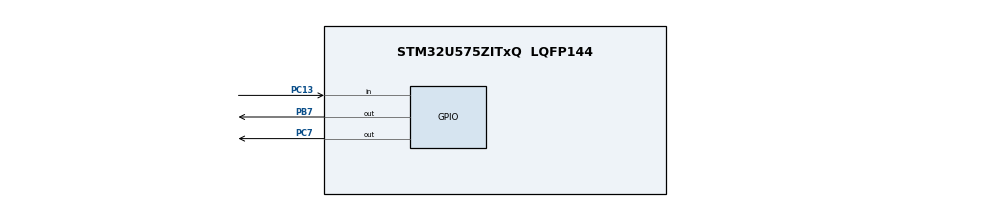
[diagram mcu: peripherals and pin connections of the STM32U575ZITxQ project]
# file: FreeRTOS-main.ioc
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CORTEX_M33_NS.userName=CORTEX_M33
Mcu.Family=STM32U5
Mcu.Name=STM32U575ZITxQ
Mcu.Package=LQFP144
NVIC.PriorityGroup=NVIC_PRIORITYGROUP_4
NVIC.TIM6_IRQn=true\:15\:0\:false\:false\:true\:false\:true\:true
NVIC.TimeBase=TIM6_IRQn
NVIC.TimeBaseIP=TIM6
PB7.Signal=GPIO_Output
PC13.Signal=GPIO_Input
PC7.Signal=GPIO_Output
ProjectManager.HeapSize=0x200
ProjectManager.StackSize=0x400
ProjectManager.TargetToolchain=STM32CubeIDE
RCC.ADCFreq_Value=16000000
RCC.EPOD_VALUE=4000000
RCC.HSE_VALUE=16000000
RCC.HSI48_VALUE=48000000
RCC.HSI_VALUE=16000000
RCC.LSE_VALUE=32768
RCC.LSIDIV_VALUE=32000
RCC.MSI_VALUE=4000000
RCC.USBFreq_Value=48000000
RCC.VCOOutputFreq_Value=516000000
VP_LPBAMQUEUE_VS_QUEUE.Mode=QUEUEMODE
VP_LPBAM_VS_SIG1.Mode=SmartRun
VP_LPBAM_VS_SIG4.Mode=LPDMA1
VP_MEMORYMAP_VS_MEMORYMAP.Mode=CurAppReg
VP_PWR_VS_SECSignals.Mode=Security/Privilege
VP_SYS_VS_tim6.Mode=TIM6
board=custom

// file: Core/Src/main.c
/* USER CODE BEGIN Header */
/**
  ******************************************************************************
  * @file           : main.c
  * @brief          : Main program body
  ******************************************************************************
  * @attention
  *
  * Copyright (c) 2024 STMicroelectronics.
  * All rights reserved.
  *
  * This software is licensed under terms that can be found in the LICENSE file
  * in the root directory of this software component.
  * If no LICENSE file comes with this software, it is provided AS-IS.
  *
  ******************************************************************************
  */
/* USER CODE END Header */
#include "main.h"

/* USER CODE BEGIN Includes */
#include "FreeRTOS.h"
#include "task.h"
#include<stdio.h>
/* USER CODE END Includes */

void SystemClock_Config(void);
static void MX_GPIO_Init(void);
/* USER CODE BEGIN PFP */
void task1handler(void *str);
void task2handler(void *str);
/* USER CODE END PFP */

/* USER CODE BEGIN 0 */
TaskHandle_t task1_handler;
TaskHandle_t task2_handler;
BaseType_t status;
/* USER CODE END 0 */

int main(void)
{

  /* MCU Configuration--------------------------------------------------------*/

  /* Reset of all peripherals, Initializes the Flash interface and the Systick. */
  HAL_Init();

  /* Configure the system clock */
  SystemClock_Config();

  /* Initialize all configured peripherals */
  MX_GPIO_Init();
  /* USER CODE BEGIN 2 */
 status =  xTaskCreate(task1handler,"Task1",20,"Hello World from Task1",2,&task1_handler);
 configASSERT(status == pdPASS);

 status =  xTaskCreate(task2handler,"Task2",20,"Hello World from Task2",2,&task2_handler);
 configASSERT(status == pdPASS);

 vTaskStartScheduler();
  /* USER CODE END 2 */

  /* Infinite loop */
  while (1)
  {

  }
}

void SystemClock_Config(void)
{
  RCC_OscInitTypeDef RCC_OscInitStruct = {0};
  RCC_ClkInitTypeDef RCC_ClkInitStruct = {0};

  /** Configure the main internal regulator output voltage
  */
  if (HAL_PWREx_ControlVoltageScaling(PWR_REGULATOR_VOLTAGE_SCALE4) != HAL_OK)
  {
    Error_Handler();
  }

  /** Initializes the CPU, AHB and APB buses clocks
  */
  RCC_OscInitStruct.OscillatorType = RCC_OSCILLATORTYPE_MSI;
  RCC_OscInitStruct.MSIState = RCC_MSI_ON;
  RCC_OscInitStruct.MSICalibrationValue = RCC_MSICALIBRATION_DEFAULT;
  RCC_OscInitStruct.MSIClockRange = RCC_MSIRANGE_4;
  RCC_OscInitStruct.PLL.PLLState = RCC_PLL_NONE;
  if (HAL_RCC_OscConfig(&RCC_OscInitStruct) != HAL_OK)
  {
    Error_Handler();
  }

  /** Initializes the CPU, AHB and APB buses clocks
  */
  RCC_ClkInitStruct.ClockType = RCC_CLOCKTYPE_HCLK|RCC_CLOCKTYPE_SYSCLK
                              |RCC_CLOCKTYPE_PCLK1|RCC_CLOCKTYPE_PCLK2
                              |RCC_CLOCKTYPE_PCLK3;
  RCC_ClkInitStruct.SYSCLKSource = RCC_SYSCLKSOURCE_MSI;
  RCC_ClkInitStruct.AHBCLKDivider = RCC_SYSCLK_DIV1;
  RCC_ClkInitStruct.APB1CLKDivider = RCC_HCLK_DIV1;
  RCC_ClkInitStruct.APB2CLKDivider = RCC_HCLK_DIV1;
  RCC_ClkInitStruct.APB3CLKDivider = RCC_HCLK_DIV1;

  if (HAL_RCC_ClockConfig(&RCC_ClkInitStruct, FLASH_LATENCY_0) != HAL_OK)
  {
    Error_Handler();
  }
}

static void MX_GPIO_Init(void)
{
  GPIO_InitTypeDef GPIO_InitStruct = {0};

  /* GPIO Ports Clock Enable */
  __HAL_RCC_GPIOC_CLK_ENABLE();
  __HAL_RCC_GPIOB_CLK_ENABLE();

  /*Configure GPIO pin Output Level */
  HAL_GPIO_WritePin(GPIOC, GPIO_PIN_7, GPIO_PIN_RESET);

  /*Configure GPIO pin Output Level */
  HAL_GPIO_WritePin(GPIOB, GPIO_PIN_7, GPIO_PIN_RESET);

  /*Configure GPIO pin : PC13 */
  GPIO_InitStruct.Pin = GPIO_PIN_13;
  GPIO_InitStruct.Mode = GPIO_MODE_INPUT;
  GPIO_InitStruct.Pull = GPIO_NOPULL;
  HAL_GPIO_Init(GPIOC, &GPIO_InitStruct);

  /*Configure GPIO pin : PC7 */
  GPIO_InitStruct.Pin = GPIO_PIN_7;
  GPIO_InitStruct.Mode = GPIO_MODE_OUTPUT_PP;
  GPIO_InitStruct.Pull = GPIO_NOPULL;
  GPIO_InitStruct.Speed = GPIO_SPEED_FREQ_LOW;
  HAL_GPIO_Init(GPIOC, &GPIO_InitStruct);

  /*Configure GPIO pin : PB7 */
  GPIO_InitStruct.Pin = GPIO_PIN_7;
  GPIO_InitStruct.Mode = GPIO_MODE_OUTPUT_PP;
  GPIO_InitStruct.Pull = GPIO_NOPULL;
  GPIO_InitStruct.Speed = GPIO_SPEED_FREQ_LOW;
  HAL_GPIO_Init(GPIOB, &GPIO_InitStruct);

}

/* USER CODE BEGIN 4 */
void task1handler(void *str)
{
	while(1)
{
	printf("%s\n",(char *)str);
}
}

void task2handler(void *str)
{
	while(1)
{
	printf("%s\n",(char *)str);
}
}
/* USER CODE END 4 */

void HAL_TIM_PeriodElapsedCallback(TIM_HandleTypeDef *htim)
{
  if (htim->Instance == TIM6) {
    HAL_IncTick();
  }
}

void Error_Handler(void)
{
  __disable_irq();
  while (1)
  {
  }
}
